AUTOSAR XML (schema 4-3-1)
standard types defined: Boolean, UInt8, SInt8, UInt16, SInt16, UInt32, SInt32, boolean, uint8, sint8, uint16, sint16, uint32, sint32
package /Components
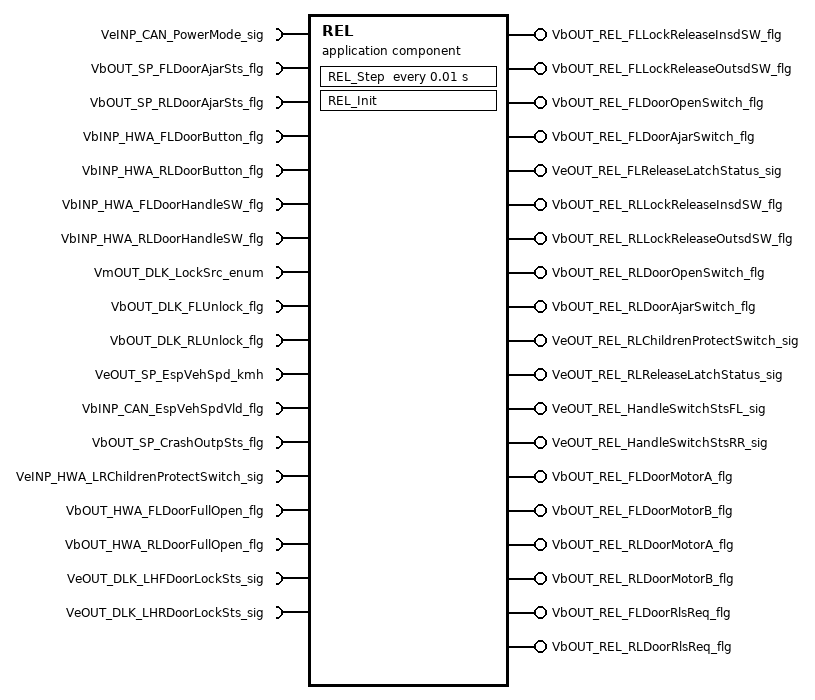
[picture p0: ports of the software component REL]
  application sw component type REL
    18 x require port:
      VeINP_CAN_PowerMode_sig: nonqueued-receiver-com-spec{data-element=VeINP_CAN_PowerMode_sig, init-value=0}, required-interface=VeINP_CAN_PowerMode_sig
      VbOUT_SP_FLDoorAjarSts_flg: nonqueued-receiver-com-spec{data-element=VbOUT_SP_FLDoorAjarSts_flg, init-value=FALSE}, required-interface=VbOUT_SP_FLDoorAjarSts_flg
      VbOUT_SP_RLDoorAjarSts_flg: nonqueued-receiver-com-spec{data-element=VbOUT_SP_RLDoorAjarSts_flg, init-value=FALSE}, required-interface=VbOUT_SP_RLDoorAjarSts_flg
      VbINP_HWA_FLDoorButton_flg: nonqueued-receiver-com-spec{data-element=VbINP_HWA_FLDoorButton_flg, init-value=FALSE}, required-interface=VbINP_HWA_FLDoorButton_flg
      VbINP_HWA_RLDoorButton_flg: nonqueued-receiver-com-spec{data-element=VbINP_HWA_RLDoorButton_flg, init-value=FALSE}, required-interface=VbINP_HWA_RLDoorButton_flg
      VbINP_HWA_FLDoorHandleSW_flg: nonqueued-receiver-com-spec{data-element=VbINP_HWA_FLDoorHandleSW_flg, init-value=FALSE}, required-interface=VbINP_HWA_FLDoorHandleSW_flg
      VbINP_HWA_RLDoorHandleSW_flg: nonqueued-receiver-com-spec{data-element=VbINP_HWA_RLDoorHandleSW_flg, init-value=FALSE}, required-interface=VbINP_HWA_RLDoorHandleSW_flg
      VmOUT_DLK_LockSrc_enum: nonqueued-receiver-com-spec{data-element=VmOUT_DLK_LockSrc_enum, init-value=0}, required-interface=VmOUT_DLK_LockSrc_enum
      VbOUT_DLK_FLUnlock_flg: nonqueued-receiver-com-spec{data-element=VbOUT_DLK_FLUnlock_flg, init-value=FALSE}, required-interface=VbOUT_DLK_FLUnlock_flg
      VbOUT_DLK_RLUnlock_flg: nonqueued-receiver-com-spec{data-element=VbOUT_DLK_RLUnlock_flg, init-value=FALSE}, required-interface=VbOUT_DLK_RLUnlock_flg
      VeOUT_SP_EspVehSpd_kmh: nonqueued-receiver-com-spec{data-element=VeOUT_SP_EspVehSpd_kmh, init-value=0}, required-interface=VeOUT_SP_EspVehSpd_kmh
      VbINP_CAN_EspVehSpdVld_flg: nonqueued-receiver-com-spec{data-element=VbINP_CAN_EspVehSpdVld_flg, init-value=FALSE}, required-interface=VbINP_CAN_EspVehSpdVld_flg
      VbOUT_SP_CrashOutpSts_flg: nonqueued-receiver-com-spec{data-element=VbOUT_SP_CrashOutpSts_flg, init-value=FALSE}, required-interface=VbOUT_SP_CrashOutpSts_flg
      VeINP_HWA_LRChildrenProtectSwitch_sig: nonqueued-receiver-com-spec{data-element=VeINP_HWA_LRChildrenProtectSwitch_sig, init-value=0}, required-interface=VeINP_HWA_LRChildrenProtectSwitch_sig
      VbOUT_HWA_FLDoorFullOpen_flg: nonqueued-receiver-com-spec{data-element=VbOUT_HWA_FLDoorFullOpen_flg, init-value=FALSE}, required-interface=VbOUT_HWA_FLDoorFullOpen_flg
      VbOUT_HWA_RLDoorFullOpen_flg: nonqueued-receiver-com-spec{data-element=VbOUT_HWA_RLDoorFullOpen_flg, init-value=FALSE}, required-interface=VbOUT_HWA_RLDoorFullOpen_flg
      VeOUT_DLK_LHFDoorLockSts_sig: nonqueued-receiver-com-spec{data-element=VeOUT_DLK_LHFDoorLockSts_sig, init-value=0}, required-interface=VeOUT_DLK_LHFDoorLockSts_sig
      VeOUT_DLK_LHRDoorLockSts_sig: nonqueued-receiver-com-spec{data-element=VeOUT_DLK_LHRDoorLockSts_sig, init-value=0}, required-interface=VeOUT_DLK_LHRDoorLockSts_sig
    19 x provide port:
      VbOUT_REL_FLLockReleaseInsdSW_flg: nonqueued-sender-com-spec{data-element=VbOUT_REL_FLLockReleaseInsdSW_flg, init-value=FALSE}, provided-interface=VbOUT_REL_FLLockReleaseInsdSW_flg
      VbOUT_REL_FLLockReleaseOutsdSW_flg: nonqueued-sender-com-spec{data-element=VbOUT_REL_FLLockReleaseOutsdSW_flg, init-value=FALSE}, provided-interface=VbOUT_REL_FLLockReleaseOutsdSW_flg
      VbOUT_REL_FLDoorOpenSwitch_flg: nonqueued-sender-com-spec{data-element=VbOUT_REL_FLDoorOpenSwitch_flg, init-value=FALSE}, provided-interface=VbOUT_REL_FLDoorOpenSwitch_flg
      VbOUT_REL_FLDoorAjarSwitch_flg: nonqueued-sender-com-spec{data-element=VbOUT_REL_FLDoorAjarSwitch_flg, init-value=FALSE}, provided-interface=VbOUT_REL_FLDoorAjarSwitch_flg
      VeOUT_REL_FLReleaseLatchStatus_sig: nonqueued-sender-com-spec{data-element=VeOUT_REL_FLReleaseLatchStatus_sig, init-value=0}, provided-interface=VeOUT_REL_FLReleaseLatchStatus_sig
      VbOUT_REL_RLLockReleaseInsdSW_flg: nonqueued-sender-com-spec{data-element=VbOUT_REL_RLLockReleaseInsdSW_flg, init-value=FALSE}, provided-interface=VbOUT_REL_RLLockReleaseInsdSW_flg
      VbOUT_REL_RLLockReleaseOutsdSW_flg: nonqueued-sender-com-spec{data-element=VbOUT_REL_RLLockReleaseOutsdSW_flg, init-value=FALSE}, provided-interface=VbOUT_REL_RLLockReleaseOutsdSW_flg
      VbOUT_REL_RLDoorOpenSwitch_flg: nonqueued-sender-com-spec{data-element=VbOUT_REL_RLDoorOpenSwitch_flg, init-value=FALSE}, provided-interface=VbOUT_REL_RLDoorOpenSwitch_flg
      VbOUT_REL_RLDoorAjarSwitch_flg: nonqueued-sender-com-spec{data-element=VbOUT_REL_RLDoorAjarSwitch_flg, init-value=FALSE}, provided-interface=VbOUT_REL_RLDoorAjarSwitch_flg
      VeOUT_REL_RLChildrenProtectSwitch_sig: nonqueued-sender-com-spec{data-element=VeOUT_REL_RLChildrenProtectSwitch_sig, init-value=0}, provided-interface=VeOUT_REL_RLChildrenProtectSwitch_sig
      VeOUT_REL_RLReleaseLatchStatus_sig: nonqueued-sender-com-spec{data-element=VeOUT_REL_RLReleaseLatchStatus_sig, init-value=0}, provided-interface=VeOUT_REL_RLReleaseLatchStatus_sig
      VeOUT_REL_HandleSwitchStsFL_sig: nonqueued-sender-com-spec{data-element=VeOUT_REL_HandleSwitchStsFL_sig, init-value=0}, provided-interface=VeOUT_REL_HandleSwitchStsFL_sig
      VeOUT_REL_HandleSwitchStsRR_sig: nonqueued-sender-com-spec{data-element=VeOUT_REL_HandleSwitchStsRR_sig, init-value=0}, provided-interface=VeOUT_REL_HandleSwitchStsRR_sig
      VbOUT_REL_FLDoorMotorA_flg: nonqueued-sender-com-spec{data-element=VbOUT_REL_FLDoorMotorA_flg, init-value=FALSE}, provided-interface=VbOUT_REL_FLDoorMotorA_flg
      VbOUT_REL_FLDoorMotorB_flg: nonqueued-sender-com-spec{data-element=VbOUT_REL_FLDoorMotorB_flg, init-value=FALSE}, provided-interface=VbOUT_REL_FLDoorMotorB_flg
      VbOUT_REL_RLDoorMotorA_flg: nonqueued-sender-com-spec{data-element=VbOUT_REL_RLDoorMotorA_flg, init-value=FALSE}, provided-interface=VbOUT_REL_RLDoorMotorA_flg
      VbOUT_REL_RLDoorMotorB_flg: nonqueued-sender-com-spec{data-element=VbOUT_REL_RLDoorMotorB_flg, init-value=FALSE}, provided-interface=VbOUT_REL_RLDoorMotorB_flg
      VbOUT_REL_FLDoorRlsReq_flg: nonqueued-sender-com-spec{data-element=VbOUT_REL_FLDoorRlsReq_flg, init-value=FALSE}, provided-interface=VbOUT_REL_FLDoorRlsReq_flg
      VbOUT_REL_RLDoorRlsReq_flg: nonqueued-sender-com-spec{data-element=VbOUT_REL_RLDoorRlsReq_flg, init-value=FALSE}, provided-interface=VbOUT_REL_RLDoorRlsReq_flg
    behavior REL: data-type-mapping=DataTypeMappingsSet, handle-termination-and-restart=NO-SUPPORT
      init event REL_InitEvent: start-on-event=REL_Init
      timing event Event_Runnable_Step: start-on-event=REL_Step, period=0.01
      runnable REL_Init
        data-send-points:
          6 x access:
            OUT_VbOUT_REL_FLDoorMotorA_flg_VbOUT_REL_FLDoorMotorA_flg: accessed-variable=VbOUT_REL_FLDoorMotorA_flg.VbOUT_REL_FLDoorMotorA_flg
            OUT_VbOUT_REL_FLDoorMotorB_flg_VbOUT_REL_FLDoorMotorB_flg: accessed-variable=VbOUT_REL_FLDoorMotorB_flg.VbOUT_REL_FLDoorMotorB_flg
            OUT_VbOUT_REL_RLDoorMotorA_flg_VbOUT_REL_RLDoorMotorA_flg: accessed-variable=VbOUT_REL_RLDoorMotorA_flg.VbOUT_REL_RLDoorMotorA_flg
            OUT_VbOUT_REL_RLDoorMotorB_flg_VbOUT_REL_RLDoorMotorB_flg: accessed-variable=VbOUT_REL_RLDoorMotorB_flg.VbOUT_REL_RLDoorMotorB_flg
            OUT_VbOUT_REL_FLDoorRlsReq_flg_VbOUT_REL_FLDoorRlsReq_flg: accessed-variable=VbOUT_REL_FLDoorRlsReq_flg.VbOUT_REL_FLDoorRlsReq_flg
            OUT_VbOUT_REL_RLDoorRlsReq_flg_VbOUT_REL_RLDoorRlsReq_flg: accessed-variable=VbOUT_REL_RLDoorRlsReq_flg.VbOUT_REL_RLDoorRlsReq_flg
      runnable REL_Step
        data-receive-point-by-arguments:
          15 x access:
            IN_VbINP_CAN_EspVehSpdVld_flg_VbINP_CAN_EspVehSpdVld_flg: accessed-variable=VbINP_CAN_EspVehSpdVld_flg.VbINP_CAN_EspVehSpdVld_flg
            IN_VbINP_HWA_FLDoorButton_flg_VbINP_HWA_FLDoorButton_flg: accessed-variable=VbINP_HWA_FLDoorButton_flg.VbINP_HWA_FLDoorButton_flg
            IN_VbINP_HWA_FLDoorHandleSW_flg_VbINP_HWA_FLDoorHandleSW_flg: accessed-variable=VbINP_HWA_FLDoorHandleSW_flg.VbINP_HWA_FLDoorHandleSW_flg
            IN_VbINP_HWA_RLDoorButton_flg_VbINP_HWA_RLDoorButton_flg: accessed-variable=VbINP_HWA_RLDoorButton_flg.VbINP_HWA_RLDoorButton_flg
            IN_VbINP_HWA_RLDoorHandleSW_flg_VbINP_HWA_RLDoorHandleSW_flg: accessed-variable=VbINP_HWA_RLDoorHandleSW_flg.VbINP_HWA_RLDoorHandleSW_flg
            IN_VbOUT_HWA_FLDoorFullOpen_flg_VbOUT_HWA_FLDoorFullOpen_flg: accessed-variable=VbOUT_HWA_FLDoorFullOpen_flg.VbOUT_HWA_FLDoorFullOpen_flg
            IN_VbOUT_HWA_RLDoorFullOpen_flg_VbOUT_HWA_RLDoorFullOpen_flg: accessed-variable=VbOUT_HWA_RLDoorFullOpen_flg.VbOUT_HWA_RLDoorFullOpen_flg
            IN_VbOUT_SP_CrashOutpSts_flg_VbOUT_SP_CrashOutpSts_flg: accessed-variable=VbOUT_SP_CrashOutpSts_flg.VbOUT_SP_CrashOutpSts_flg
            IN_VbOUT_SP_FLDoorAjarSts_flg_VbOUT_SP_FLDoorAjarSts_flg: accessed-variable=VbOUT_SP_FLDoorAjarSts_flg.VbOUT_SP_FLDoorAjarSts_flg
            IN_VbOUT_SP_RLDoorAjarSts_flg_VbOUT_SP_RLDoorAjarSts_flg: accessed-variable=VbOUT_SP_RLDoorAjarSts_flg.VbOUT_SP_RLDoorAjarSts_flg
            IN_VeINP_CAN_PowerMode_sig_VeINP_CAN_PowerMode_sig: accessed-variable=VeINP_CAN_PowerMode_sig.VeINP_CAN_PowerMode_sig
            IN_VeINP_HWA_LRChildrenProtectSwitch_sig_VeINP_HWA_LRChildrenProtectSwitch_sig: accessed-variable=VeINP_HWA_LRChildrenProtectSwitch_sig.VeINP_HWA_LRChildrenProtectSwitch_sig
            IN_VeOUT_DLK_LHFDoorLockSts_sig_VeOUT_DLK_LHFDoorLockSts_sig: accessed-variable=VeOUT_DLK_LHFDoorLockSts_sig.VeOUT_DLK_LHFDoorLockSts_sig
            IN_VeOUT_DLK_LHRDoorLockSts_sig_VeOUT_DLK_LHRDoorLockSts_sig: accessed-variable=VeOUT_DLK_LHRDoorLockSts_sig.VeOUT_DLK_LHRDoorLockSts_sig
            IN_VeOUT_SP_EspVehSpd_kmh_VeOUT_SP_EspVehSpd_kmh: accessed-variable=VeOUT_SP_EspVehSpd_kmh.VeOUT_SP_EspVehSpd_kmh
        data-send-points:
          19 x access:
            OUT_VbOUT_REL_FLLockReleaseInsdSW_flg_VbOUT_REL_FLLockReleaseInsdSW_flg: accessed-variable=VbOUT_REL_FLLockReleaseInsdSW_flg.VbOUT_REL_FLLockReleaseInsdSW_flg
            OUT_VbOUT_REL_FLLockReleaseOutsdSW_flg_VbOUT_REL_FLLockReleaseOutsdSW_flg: accessed-variable=VbOUT_REL_FLLockReleaseOutsdSW_flg.VbOUT_REL_FLLockReleaseOutsdSW_flg
            OUT_VbOUT_REL_FLDoorOpenSwitch_flg_VbOUT_REL_FLDoorOpenSwitch_flg: accessed-variable=VbOUT_REL_FLDoorOpenSwitch_flg.VbOUT_REL_FLDoorOpenSwitch_flg
            OUT_VbOUT_REL_FLDoorAjarSwitch_flg_VbOUT_REL_FLDoorAjarSwitch_flg: accessed-variable=VbOUT_REL_FLDoorAjarSwitch_flg.VbOUT_REL_FLDoorAjarSwitch_flg
            OUT_VeOUT_REL_FLReleaseLatchStatus_sig_VeOUT_REL_FLReleaseLatchStatus_sig: accessed-variable=VeOUT_REL_FLReleaseLatchStatus_sig.VeOUT_REL_FLReleaseLatchStatus_sig
            OUT_VbOUT_REL_RLLockReleaseInsdSW_flg_VbOUT_REL_RLLockReleaseInsdSW_flg: accessed-variable=VbOUT_REL_RLLockReleaseInsdSW_flg.VbOUT_REL_RLLockReleaseInsdSW_flg
            OUT_VbOUT_REL_RLLockReleaseOutsdSW_flg_VbOUT_REL_RLLockReleaseOutsdSW_flg: accessed-variable=VbOUT_REL_RLLockReleaseOutsdSW_flg.VbOUT_REL_RLLockReleaseOutsdSW_flg
            OUT_VbOUT_REL_RLDoorOpenSwitch_flg_VbOUT_REL_RLDoorOpenSwitch_flg: accessed-variable=VbOUT_REL_RLDoorOpenSwitch_flg.VbOUT_REL_RLDoorOpenSwitch_flg
            OUT_VbOUT_REL_RLDoorAjarSwitch_flg_VbOUT_REL_RLDoorAjarSwitch_flg: accessed-variable=VbOUT_REL_RLDoorAjarSwitch_flg.VbOUT_REL_RLDoorAjarSwitch_flg
            OUT_VeOUT_REL_RLChildrenProtectSwitch_sig_VeOUT_REL_RLChildrenProtectSwitch_sig: accessed-variable=VeOUT_REL_RLChildrenProtectSwitch_sig.VeOUT_REL_RLChildrenProtectSwitch_sig
            OUT_VeOUT_REL_RLReleaseLatchStatus_sig_VeOUT_REL_RLReleaseLatchStatus_sig: accessed-variable=VeOUT_REL_RLReleaseLatchStatus_sig.VeOUT_REL_RLReleaseLatchStatus_sig
            OUT_VeOUT_REL_HandleSwitchStsFL_sig_VeOUT_REL_HandleSwitchStsFL_sig: accessed-variable=VeOUT_REL_HandleSwitchStsFL_sig.VeOUT_REL_HandleSwitchStsFL_sig
            OUT_VeOUT_REL_HandleSwitchStsRR_sig_VeOUT_REL_HandleSwitchStsRR_sig: accessed-variable=VeOUT_REL_HandleSwitchStsRR_sig.VeOUT_REL_HandleSwitchStsRR_sig
            OUT_VbOUT_REL_FLDoorMotorA_flg_VbOUT_REL_FLDoorMotorA_flg: accessed-variable=VbOUT_REL_FLDoorMotorA_flg.VbOUT_REL_FLDoorMotorA_flg
            OUT_VbOUT_REL_FLDoorMotorB_flg_VbOUT_REL_FLDoorMotorB_flg: accessed-variable=VbOUT_REL_FLDoorMotorB_flg.VbOUT_REL_FLDoorMotorB_flg
            OUT_VbOUT_REL_RLDoorMotorA_flg_VbOUT_REL_RLDoorMotorA_flg: accessed-variable=VbOUT_REL_RLDoorMotorA_flg.VbOUT_REL_RLDoorMotorA_flg
            OUT_VbOUT_REL_RLDoorMotorB_flg_VbOUT_REL_RLDoorMotorB_flg: accessed-variable=VbOUT_REL_RLDoorMotorB_flg.VbOUT_REL_RLDoorMotorB_flg
            OUT_VbOUT_REL_FLDoorRlsReq_flg_VbOUT_REL_FLDoorRlsReq_flg: accessed-variable=VbOUT_REL_FLDoorRlsReq_flg.VbOUT_REL_FLDoorRlsReq_flg
            OUT_VbOUT_REL_RLDoorRlsReq_flg_VbOUT_REL_RLDoorRlsReq_flg: accessed-variable=VbOUT_REL_RLDoorRlsReq_flg.VbOUT_REL_RLDoorRlsReq_flg
package /DataTypes/ApplicationDataTypes
  application record data type TURN_DIAG_STRUCT: category=STRUCTURE, sw-calibration-access=READ-WRITE
    5 x application record element:
      OpenLoad: category=BOOLEAN, type=Boolean
      Overload: category=BOOLEAN, type=Boolean
      NormA2D: category=VALUE, type=UInt8
      Turn_LTH: category=VALUE, type=UInt8
      TurnCalib_th: category=VALUE, type=UInt8
  application array data type rt_Array_UInt8_8: category=ARRAY, sw-calibration-access=READ-WRITE
    element rt_Array_UInt8_8: category=VALUE, type=UInt8, array-size-semantics=FIXED-SIZE, max-number-of-elements=8
  7 x app type, all with sw-calibration-access=READ-WRITE:
    Boolean: category=BOOLEAN, compu {0=FALSE, 1=TRUE}
    UInt8: category=VALUE, compu {identical}, range phys 0..255
    SInt8: category=VALUE, compu {identical}, range phys -128..127
    UInt16: category=VALUE, compu {identical}, range phys 0..65535
    SInt16: category=VALUE, compu {identical}, range phys -32768..32767
    UInt32: category=VALUE, compu {identical}, range phys 0..4294967295
    SInt32: category=VALUE, compu {identical}, range phys -2147483648..2147483647
package /DataTypes/DataTypeMappings
  data type mapping set DataTypeMappingsSet
    data-type-maps:
      application-data-type=Boolean, implementation-data-type=Boolean
      application-data-type=UInt8, implementation-data-type=UInt8
      application-data-type=SInt8, implementation-data-type=SInt8
      application-data-type=UInt16, implementation-data-type=UInt16
      application-data-type=SInt16, implementation-data-type=SInt16
      application-data-type=UInt32, implementation-data-type=UInt32
      application-data-type=SInt32, implementation-data-type=SInt32
      application-data-type=TURN_DIAG_STRUCT, implementation-data-type=TURN_DIAG_STRUCT
      application-data-type=rt_Array_UInt8_8, implementation-data-type=rt_Array_UInt8_8
package /DataTypes/ImplementationDataTypes
  impl type TURN_DIAG_STRUCT: category=STRUCTURE
    5 x element, all with category=TYPE_REFERENCE:
      OpenLoad: implementation-data-type=Boolean
      Overload: implementation-data-type=Boolean
      NormA2D: implementation-data-type=UInt8
      Turn_LTH: implementation-data-type=UInt8
      TurnCalib_th: implementation-data-type=UInt8
  impl type rt_Array_UInt8_8: category=ARRAY
    element rt_Array_UInt8_8: array-size=8, array-size-semantics=FIXED-SIZE, implementation-data-type=UInt8
package /DataTypes/SwAddrMethods
  sw addr method CODE: section-type=CODE
  sw addr method CONST: section-type=CONST
  sw addr method VAR: section-type=VAR
package /DataTypes/Units
  unit NoUnit: factor-si-to-unit=1, offset-si-to-unit=0
package /Interfaces
  37 x sender receiver interface:
    VeINP_CAN_PowerMode_sig
      data VeINP_CAN_PowerMode_sig: category=VALUE, sw-calibration-access=READ-ONLY, type=UInt8
    VbOUT_SP_FLDoorAjarSts_flg
      data VbOUT_SP_FLDoorAjarSts_flg: category=BOOLEAN, sw-calibration-access=READ-ONLY, type=Boolean
    VbOUT_SP_RLDoorAjarSts_flg
      data VbOUT_SP_RLDoorAjarSts_flg: category=BOOLEAN, sw-calibration-access=READ-ONLY, type=Boolean
    VbINP_HWA_FLDoorButton_flg
      data VbINP_HWA_FLDoorButton_flg: category=BOOLEAN, sw-calibration-access=READ-ONLY, type=Boolean
    VbINP_HWA_RLDoorButton_flg
      data VbINP_HWA_RLDoorButton_flg: category=BOOLEAN, sw-calibration-access=READ-ONLY, type=Boolean
    VbINP_HWA_FLDoorHandleSW_flg
      data VbINP_HWA_FLDoorHandleSW_flg: category=BOOLEAN, sw-calibration-access=READ-ONLY, type=Boolean
    VbINP_HWA_RLDoorHandleSW_flg
      data VbINP_HWA_RLDoorHandleSW_flg: category=BOOLEAN, sw-calibration-access=READ-ONLY, type=Boolean
    VmOUT_DLK_LockSrc_enum
      data VmOUT_DLK_LockSrc_enum: category=VALUE, sw-calibration-access=READ-ONLY, type=UInt8
    VbOUT_DLK_FLUnlock_flg
      data VbOUT_DLK_FLUnlock_flg: category=BOOLEAN, sw-calibration-access=READ-ONLY, type=Boolean
    VbOUT_DLK_RLUnlock_flg
      data VbOUT_DLK_RLUnlock_flg: category=BOOLEAN, sw-calibration-access=READ-ONLY, type=Boolean
    VeOUT_SP_EspVehSpd_kmh
      data VeOUT_SP_EspVehSpd_kmh: category=VALUE, sw-calibration-access=READ-ONLY, type=UInt8
    VbINP_CAN_EspVehSpdVld_flg
      data VbINP_CAN_EspVehSpdVld_flg: category=BOOLEAN, sw-calibration-access=READ-ONLY, type=Boolean
    VbOUT_SP_CrashOutpSts_flg
      data VbOUT_SP_CrashOutpSts_flg: category=BOOLEAN, sw-calibration-access=READ-ONLY, type=Boolean
    VeINP_HWA_LRChildrenProtectSwitch_sig
      data VeINP_HWA_LRChildrenProtectSwitch_sig: category=VALUE, sw-calibration-access=READ-ONLY, type=UInt8
    VbOUT_HWA_FLDoorFullOpen_flg
      data VbOUT_HWA_FLDoorFullOpen_flg: category=BOOLEAN, sw-calibration-access=READ-ONLY, type=Boolean
    VbOUT_HWA_RLDoorFullOpen_flg
      data VbOUT_HWA_RLDoorFullOpen_flg: category=BOOLEAN, sw-calibration-access=READ-ONLY, type=Boolean
    VeOUT_DLK_LHFDoorLockSts_sig
      data VeOUT_DLK_LHFDoorLockSts_sig: category=VALUE, sw-calibration-access=READ-ONLY, type=UInt8
    VeOUT_DLK_LHRDoorLockSts_sig
      data VeOUT_DLK_LHRDoorLockSts_sig: category=VALUE, sw-calibration-access=READ-ONLY, type=UInt8
    VbOUT_REL_FLLockReleaseInsdSW_flg
      data VbOUT_REL_FLLockReleaseInsdSW_flg: category=BOOLEAN, sw-calibration-access=READ-ONLY, type=Boolean
    VbOUT_REL_FLLockReleaseOutsdSW_flg
      data VbOUT_REL_FLLockReleaseOutsdSW_flg: category=BOOLEAN, sw-calibration-access=READ-ONLY, type=Boolean
    VbOUT_REL_FLDoorOpenSwitch_flg
      data VbOUT_REL_FLDoorOpenSwitch_flg: category=BOOLEAN, sw-calibration-access=READ-ONLY, type=Boolean
    VbOUT_REL_FLDoorAjarSwitch_flg
      data VbOUT_REL_FLDoorAjarSwitch_flg: category=BOOLEAN, sw-calibration-access=READ-ONLY, type=Boolean
    VeOUT_REL_FLReleaseLatchStatus_sig
      data VeOUT_REL_FLReleaseLatchStatus_sig: category=VALUE, sw-calibration-access=READ-ONLY, type=UInt8
    VbOUT_REL_RLLockReleaseInsdSW_flg
      data VbOUT_REL_RLLockReleaseInsdSW_flg: category=BOOLEAN, sw-calibration-access=READ-ONLY, type=Boolean
    VbOUT_REL_RLLockReleaseOutsdSW_flg
      data VbOUT_REL_RLLockReleaseOutsdSW_flg: category=BOOLEAN, sw-calibration-access=READ-ONLY, type=Boolean
    VbOUT_REL_RLDoorOpenSwitch_flg
      data VbOUT_REL_RLDoorOpenSwitch_flg: category=BOOLEAN, sw-calibration-access=READ-ONLY, type=Boolean
    VbOUT_REL_RLDoorAjarSwitch_flg
      data VbOUT_REL_RLDoorAjarSwitch_flg: category=BOOLEAN, sw-calibration-access=READ-ONLY, type=Boolean
    VeOUT_REL_RLChildrenProtectSwitch_sig
      data VeOUT_REL_RLChildrenProtectSwitch_sig: category=VALUE, sw-calibration-access=READ-ONLY, type=UInt8
    VeOUT_REL_RLReleaseLatchStatus_sig
      data VeOUT_REL_RLReleaseLatchStatus_sig: category=VALUE, sw-calibration-access=READ-ONLY, type=UInt8
    VeOUT_REL_HandleSwitchStsFL_sig
      data VeOUT_REL_HandleSwitchStsFL_sig: category=VALUE, sw-calibration-access=READ-ONLY, type=UInt8
    VeOUT_REL_HandleSwitchStsRR_sig
      data VeOUT_REL_HandleSwitchStsRR_sig: category=VALUE, sw-calibration-access=READ-ONLY, type=UInt8
    VbOUT_REL_FLDoorMotorA_flg
      data VbOUT_REL_FLDoorMotorA_flg: category=BOOLEAN, sw-calibration-access=READ-ONLY, type=Boolean
    VbOUT_REL_FLDoorMotorB_flg
      data VbOUT_REL_FLDoorMotorB_flg: category=BOOLEAN, sw-calibration-access=READ-ONLY, type=Boolean
    VbOUT_REL_RLDoorMotorA_flg
      data VbOUT_REL_RLDoorMotorA_flg: category=BOOLEAN, sw-calibration-access=READ-ONLY, type=Boolean
    VbOUT_REL_RLDoorMotorB_flg
      data VbOUT_REL_RLDoorMotorB_flg: category=BOOLEAN, sw-calibration-access=READ-ONLY, type=Boolean
    VbOUT_REL_FLDoorRlsReq_flg
      data VbOUT_REL_FLDoorRlsReq_flg: category=BOOLEAN, sw-calibration-access=READ-ONLY, type=Boolean
    VbOUT_REL_RLDoorRlsReq_flg
      data VbOUT_REL_RLDoorRlsReq_flg: category=BOOLEAN, sw-calibration-access=READ-ONLY, type=Boolean
